# M365 register map
File version: 0.1
CPU: 
Registers are 32-bit, read-write, reset 0x0 unless marked. A register's access mark holds for its fields unless they carry their own. Offsets are from the block's base; [hi:lo] are bit positions; {n}, {i} and the like mark numbered series.

## UDFS2 — UDC2(USB -Spec2.0 Device contoller)
Base 0x40008200
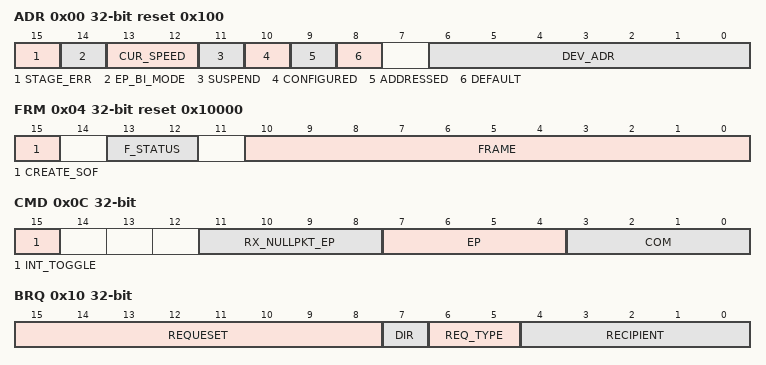
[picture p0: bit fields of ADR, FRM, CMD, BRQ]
0x00 ADR reset 0x100 — UDC2 Address State
  [15] STAGE_ERR, [14] EP_BI_MODE, [13:12] CUR_SPEED ro, [11] SUSPEND ro, [10] CONFIGURED, [9] ADDRESSED, [8] DEFAULT, [6:0] DEV_ADR
0x04 FRM reset 0x10000 — UDC2 Frame
  [15] CREATE_SOF, [13:12] F_STATUS ro, [10:0] FRAME ro
0x0C CMD — UDC2 Command
  [15] INT_TOGGLE, [11:8] RX_NULLPKT_EP ro, [7:4] EP, [3:0] COM
0x10 BRQ ro — UDC2 bRequest-bmRequest Type
  [15:8] REQUESET, [7] DIR, [6:5] REQ_TYPE, [4:0] RECIPIENT
0x14 WVL ro — UDC2 wValue
  [15:0] VALUE
0x18 WIDX ro — UDC2 wIndex
  [15:0] INDEX
0x1C WLGTH ro — UDC2 wLength
  [15:0] LENGTH
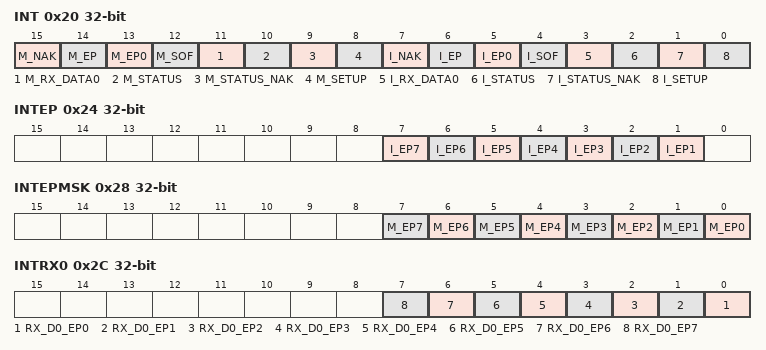
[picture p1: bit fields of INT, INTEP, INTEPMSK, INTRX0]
0x20 INT — UDC2 INT
  [15] M_NAK, [14] M_EP, [13] M_EP0, [12] M_SOF, [11] M_RX_DATA0, [10] M_STATUS, [9] M_STATUS_NAK, [8] M_SETUP, [7] I_NAK, [6] I_EP, [5] I_EP0, [4] I_SOF, [3] I_RX_DATA0, [2] I_STATUS, [1] I_STATUS_NAK, [0] I_SETUP
0x24 INTEP — UDC2 INT_EP
  [n] I_EP{n} (n=1..7)
0x28 INTEPMSK — UDC2 INT_EP_MASK
  [n] M_EP{n} (n=0..7)
0x2C INTRX0 — UDC2 INT RX DATA0
  [n] RX_D0_EP{n} (n=0..7)
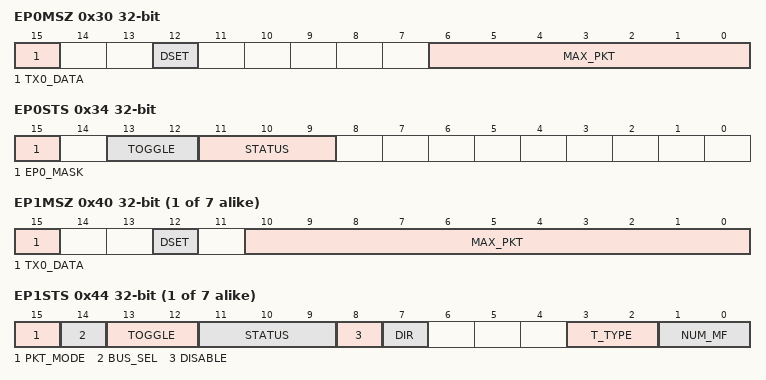
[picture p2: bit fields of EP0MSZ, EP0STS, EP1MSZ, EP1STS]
0x30 EP0MSZ — UDC2 EP0 Max Packet Size
  [15] TX0_DATA ro, [12] DSET ro, [6:0] MAX_PKT
0x34 EP0STS ro — UDC2 EP0 Status
  [15] EP0_MASK, [13:12] TOGGLE, [11:9] STATUS
0x38 EP0DSZ ro — UDC2 EP0 Data Size
  [6:0] SIZE
{0x3C+0x10*i} EP{i}FIFO (i=0..7) — UDC2 EP{i} FIFO
  [15:0] DATA
{0x30+0x10*i} EP{i}MSZ (i=1..7) — UDC2 EP{i} Max Packet Size
  [15] TX0_DATA ro, [12] DSET ro, [10:0] MAX_PKT
{0x34+0x10*i} EP{i}STS (i=1..7) — UDC2 EP{i} Status
  [15] PKT_MODE, [14] BUS_SEL, [13:12] TOGGLE ro, [11:9] STATUS ro, [8] DISABLE ro, [7] DIR, [3:2] T_TYPE, [1:0] NUM_MF
{0x38+0x10*i} EP{i}DSZ ro (i=1..7) — UDC2 EP{i} Data Size
  [10:0] SIZE
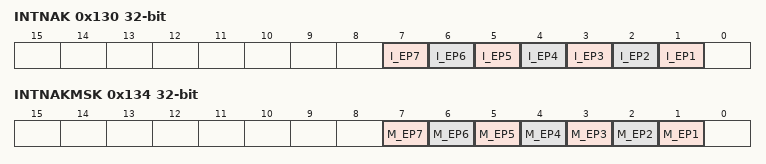
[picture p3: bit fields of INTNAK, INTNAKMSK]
0x130 INTNAK — UDC2 INT NAK
  [n] I_EP{n} (n=1..7)
0x134 INTNAKMSK — UDC2 INT NAK MASK
  [n] M_EP{n} (n=1..7)

## AD — Analog-to-Digital Converter (AD)
Base 0x40050000
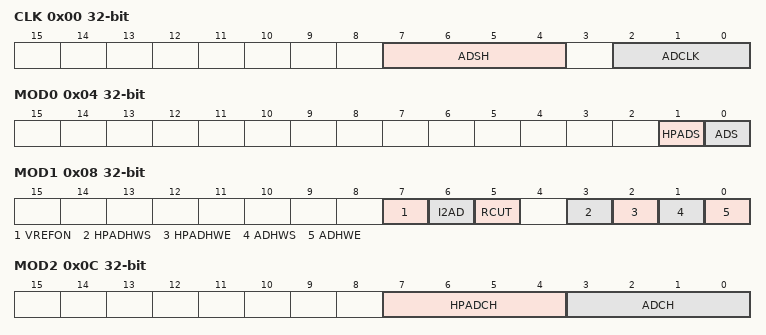
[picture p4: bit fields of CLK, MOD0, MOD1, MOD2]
0x00 CLK — AD Conversion Clock Setting Register
  [7:4] ADSH, [2:0] ADCLK
0x04 MOD0 wo — AD Mode Control Register 0
  [1] HPADS, [0] ADS
0x08 MOD1 — AD Mode Control Register 1
  [7] VREFON, [6] I2AD, [5] RCUT, [3] HPADHWS, [2] HPADHWE, [1] ADHWS, [0] ADHWE
0x0C MOD2 — AD Mode Control Register 2
  [7:4] HPADCH, [3:0] ADCH
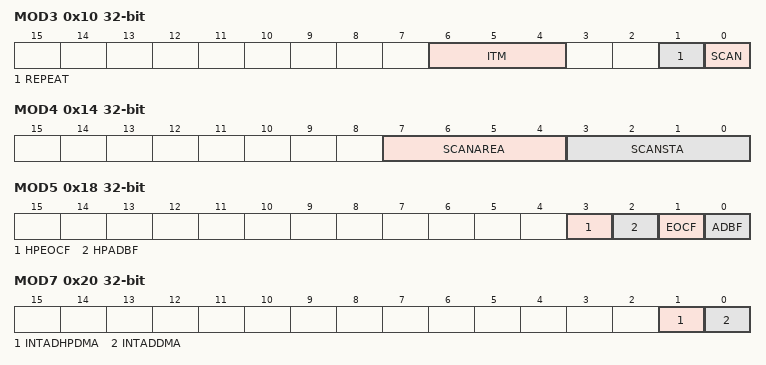
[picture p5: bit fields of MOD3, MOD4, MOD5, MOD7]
0x10 MOD3 — AD Mode Control Register 3
  [6:4] ITM, [1] REPEAT, [0] SCAN
0x14 MOD4 — AD Mode Control Register 4
  [7:4] SCANAREA, [3:0] SCANSTA
0x18 MOD5 ro — AD Mode Control Register 5
  [3] HPEOCF, [2] HPADBF, [1] EOCF, [0] ADBF
0x1C MOD6 wo — AD Mode Control Register 6
  [1:0] ADRST
0x20 MOD7 — AD Mode Control Register 7
  [1] INTADHPDMA, [0] INTADDMA
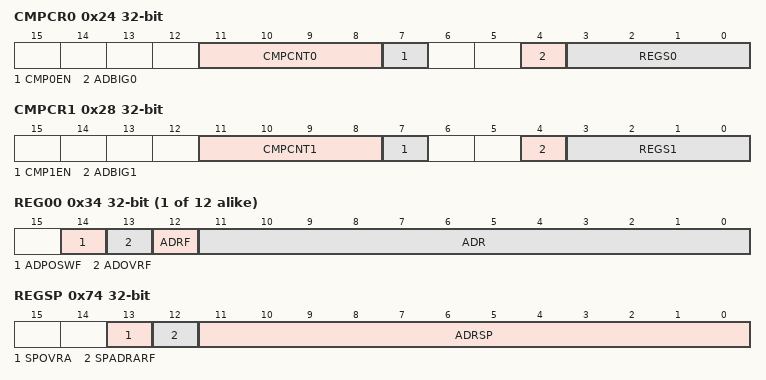
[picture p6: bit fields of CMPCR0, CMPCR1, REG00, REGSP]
0x24 CMPCR0 — AD Monitoring Setting Register 0
  [11:8] CMPCNT0, [7] CMP0EN, [4] ADBIG0, [3:0] REGS0
0x28 CMPCR1 — AD Monitoring Setting Register 1
  [11:8] CMPCNT1, [7] CMP1EN, [4] ADBIG1, [3:0] REGS1
0x2C CMP0 — AD Conversion Result Comparison Register 0
  [11:0] AD0CMP
0x30 CMP1 — AD Conversion Result Comparison Register 1
  [11:0] AD1CMP
{0x34+4i} REG{i:02} ro (i=0..11) — AD Conversion Result Register {i:02}
  [14] ADPOSWF, [13] ADOVRF, [12] ADRF, [11:0] ADR
0x74 REGSP ro — AD Conversion Result Register SP
  [13] SPOVRA, [12] SPADRARF, [11:0] ADRSP

## PA — General Purpose Input_Output Port (PA)
Base 0x400C0000
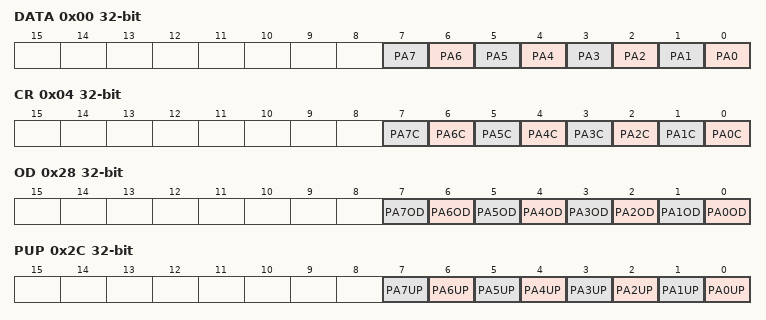
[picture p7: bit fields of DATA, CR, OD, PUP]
0x00 DATA — PA Data Register
  [n] PA{n} (n=0..7)
0x04 CR — PA Control Register
  [n] PA{n}C (n=0..7)
0x28 OD — PA Open Drain Control Register
  [n] PA{n}OD (n=0..7)
0x2C PUP — PA Pull-Up Control Register
  [n] PA{n}UP (n=0..7)
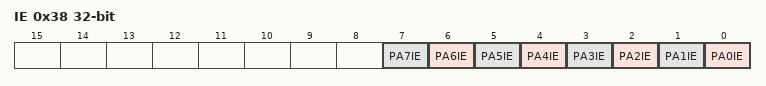
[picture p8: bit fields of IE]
0x38 IE — PA Input Enable Control Register
  [n] PA{n}IE (n=0..7)

## PB — General Purpose Input_Output Port (PB)
Base 0x400C0100
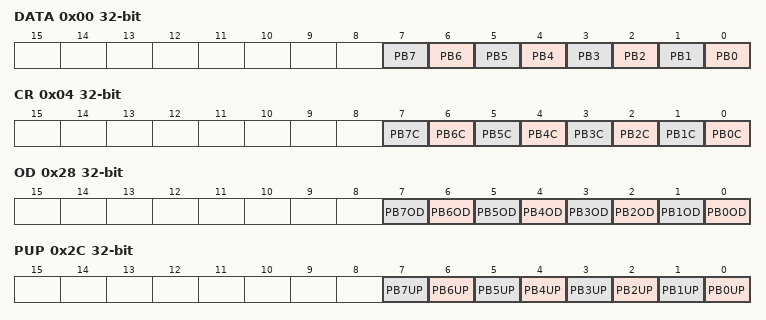
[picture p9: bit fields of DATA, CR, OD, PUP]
0x00 DATA — PB Data Register
  [n] PB{n} (n=0..7)
0x04 CR — PB Control Register
  [n] PB{n}C (n=0..7)
0x28 OD — PB Open Drain Control Register
  [n] PB{n}OD (n=0..7)
0x2C PUP — PB Pull-Up Control Register
  [n] PB{n}UP (n=0..7)
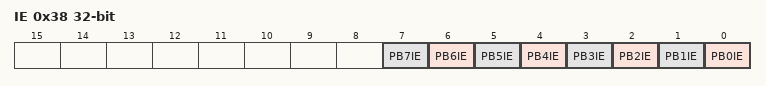
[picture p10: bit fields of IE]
0x38 IE — PB Input Enable Control Register
  [n] PB{n}IE (n=0..7)
